VERSION ""

NS_ :

BS_:

BU_: AEB_ECU ABS_ECU ECM EPS_ECU IPC BCM CGW Vector__XXX

/* ─────────────────────────────────────────────────────────────────────
 *  SUV2026 — CAN-HS1 (ADAS Safety Bus) — 500 Kbps
 *  Source: ADAS_HS1_Communication_Matrix_v1.0
 *  Version: 1.0.0
 *  Author: Network Architecture Team
 *  Status: TRAINING REFERENCE
 * ───────────────────────────────────────────────────────────────────── */

/* ─── MESSAGES ─────────────────────────────────────────────────────── */

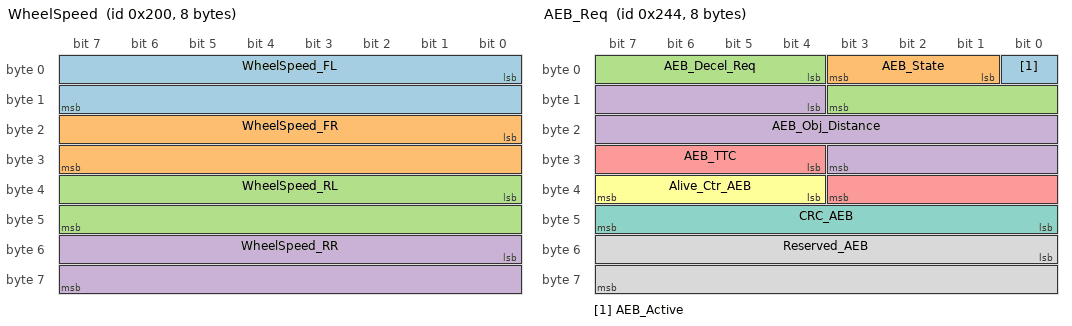
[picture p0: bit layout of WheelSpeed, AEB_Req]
BO_ 512 WheelSpeed: 8 ABS_ECU
 SG_ WheelSpeed_FL : 0|16@1+  (0.01,0) [0|300]    "km/h"  AEB_ECU,ECM,EPS_ECU,CGW
 SG_ WheelSpeed_FR : 16|16@1+ (0.01,0) [0|300]    "km/h"  AEB_ECU,ECM,EPS_ECU,CGW
 SG_ WheelSpeed_RL : 32|16@1+ (0.01,0) [0|300]    "km/h"  AEB_ECU,ECM,CGW
 SG_ WheelSpeed_RR : 48|16@1+ (0.01,0) [0|300]    "km/h"  AEB_ECU,ECM,CGW

BO_ 580 AEB_Req: 8 AEB_ECU
 SG_ AEB_Active        : 0|1@1+   (1,0)     [0|1]       ""       CGW,IPC,ECM,BCM
 SG_ AEB_State         : 1|3@1+   (1,0)     [0|7]       ""       CGW,IPC,ECM,BCM
 SG_ AEB_Decel_Req     : 4|8@1+   (0.1,0)   [0|25.5]   "m/s2"   CGW,IPC,ECM
 SG_ AEB_Obj_Distance  : 12|16@1+ (0.01,0)  [0|655.35] "m"      CGW,IPC
 SG_ AEB_TTC           : 28|8@1+  (0.01,0)  [0|2.55]   "s"      CGW,IPC
 SG_ Alive_Ctr_AEB     : 36|4@1+  (1,0)     [0|14]     ""       CGW,IPC
 SG_ CRC_AEB           : 40|8@1+  (1,0)     [0|255]    ""       CGW,IPC
 SG_ Reserved_AEB      : 48|16@1+ (1,0)     [0|65535]  ""       Vector__XXX

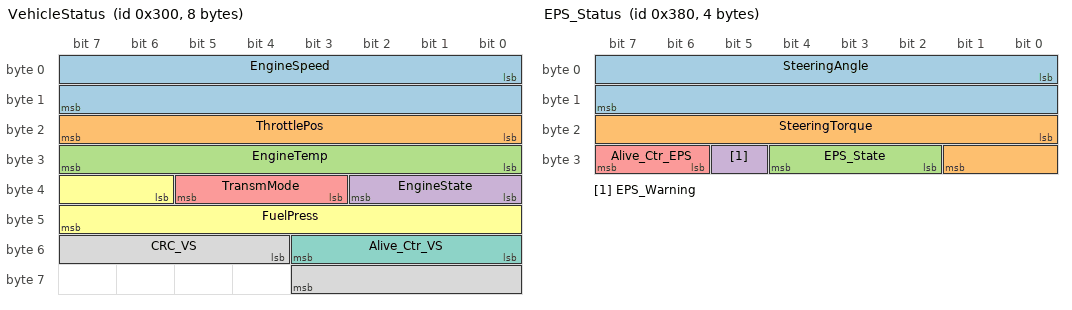
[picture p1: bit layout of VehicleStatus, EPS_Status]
BO_ 768 VehicleStatus: 8 ECM
 SG_ EngineSpeed    : 0|16@1+  (0.25,0)   [0|16383.75] "rpm"   AEB_ECU,IPC,ABS_ECU,CGW
 SG_ ThrottlePos    : 16|8@1+  (0.4,0)    [0|100]      "%"     AEB_ECU,IPC
 SG_ EngineTemp     : 24|8@1+  (0.5,-40)  [-40|87.5]   "degC"  IPC,BCM
 SG_ EngineState    : 32|3@1+  (1,0)      [0|6]        ""      AEB_ECU,IPC,BCM,CGW
 SG_ TransmMode     : 35|3@1+  (1,0)      [0|5]        ""      IPC,BCM
 SG_ FuelPress      : 38|10@1+ (0.1,0)    [0|102.3]    "bar"   IPC
 SG_ Alive_Ctr_VS   : 48|4@1+  (1,0)      [0|14]       ""      AEB_ECU,IPC,CGW
 SG_ CRC_VS         : 52|8@1+  (1,0)      [0|255]      ""      AEB_ECU,IPC,CGW

BO_ 896 EPS_Status: 4 EPS_ECU
 SG_ SteeringAngle  : 0|16@1-  (0.1,0)     [-3276.8|3276.7] "deg"  AEB_ECU,IPC,CGW
 SG_ SteeringTorque : 16|10@1- (0.01,-5.12) [-5.12|5.11]    "Nm"   IPC
 SG_ EPS_State      : 26|3@1+  (1,0)        [0|7]            ""     IPC,CGW,BCM
 SG_ EPS_Warning    : 29|1@1+  (1,0)        [0|1]            ""     IPC,BCM
 SG_ Alive_Ctr_EPS  : 30|2@1+  (1,0)        [0|3]            ""     AEB_ECU

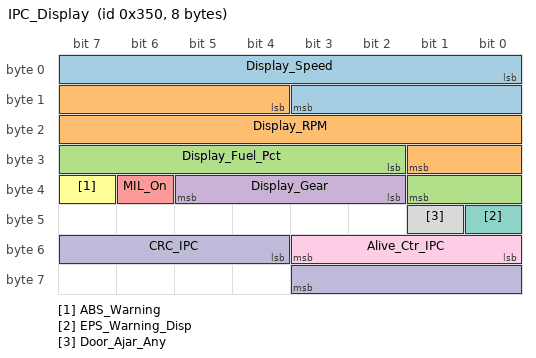
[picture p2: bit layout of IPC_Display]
BO_ 848 IPC_Display: 8 IPC
 SG_ Display_Speed     : 0|12@1+  (0.1,0)  [0|409.5]  "km/h"  CGW
 SG_ Display_RPM       : 12|14@1+ (0.5,0)  [0|8191.5] "rpm"   CGW
 SG_ Display_Fuel_Pct  : 26|8@1+  (0.5,0)  [0|127.5]  "%"     CGW
 SG_ Display_Gear      : 34|4@1+  (1,0)    [0|9]      ""      CGW
 SG_ MIL_On            : 38|1@1+  (1,0)    [0|1]      ""      CGW
 SG_ ABS_Warning       : 39|1@1+  (1,0)    [0|1]      ""      CGW
 SG_ EPS_Warning_Disp  : 40|1@1+  (1,0)    [0|1]      ""      CGW
 SG_ Door_Ajar_Any     : 41|1@1+  (1,0)    [0|1]      ""      CGW
 SG_ Alive_Ctr_IPC     : 48|4@1+  (1,0)    [0|14]     ""      CGW
 SG_ CRC_IPC           : 52|8@1+  (1,0)    [0|255]    ""      CGW

BO_ 1056 BCM_Status: 6 BCM
 SG_ DoorFL_Status  : 0|2@1+  (1,0) [0|3]   ""  CGW,IPC,AEB_ECU
 SG_ DoorFR_Status  : 2|2@1+  (1,0) [0|3]   ""  CGW,IPC
 SG_ DoorRL_Status  : 4|2@1+  (1,0) [0|3]   ""  CGW,IPC
 SG_ DoorRR_Status  : 6|2@1+  (1,0) [0|3]   ""  CGW,IPC
 SG_ Hood_Status    : 8|1@1+  (1,0) [0|1]   ""  CGW,IPC
 SG_ Trunk_Status   : 9|1@1+  (1,0) [0|1]   ""  CGW,IPC
 SG_ IgnitionState  : 10|3@1+ (1,0) [0|4]   ""  CGW,IPC,AEB_ECU
 SG_ HazardActive   : 13|1@1+ (1,0) [0|1]   ""  CGW,IPC
 SG_ LowBeam        : 14|1@1+ (1,0) [0|1]   ""  CGW,IPC
 SG_ HighBeam       : 15|1@1+ (1,0) [0|1]   ""  CGW,IPC
 SG_ WiperState     : 16|3@1+ (1,0) [0|4]   ""  CGW,IPC
 SG_ Alive_Ctr_BCM  : 40|4@1+ (1,0) [0|14]  ""  CGW,IPC
 SG_ CRC_BCM        : 44|8@1+ (1,0) [0|255] ""  CGW,IPC

/* ─── VALUE DEFINITIONS ─────────────────────────────────────────────── */

  0 "OFF"
  1 "STANDBY"
  2 "WARNING"
  3 "ACTIVE"
  4 "FAULT"
  5 "DEGRADED"
  6 "OVERRIDE"
  7 "NOT_AVAILABLE" ;

  0 "OFF"
  1 "CRANKING"
  2 "IDLE"
  3 "RUNNING"
  4 "OVERHEATING"
  5 "SHUTDOWN"
  6 "FAULT" ;

  0 "PARK"
  1 "REVERSE"
  2 "NEUTRAL"
  3 "DRIVE"
  4 "SPORT"
  5 "MANUAL" ;

  0 "INIT"
  1 "ACTIVE"
  2 "DEGRADED"
  3 "FAULT"
  4 "OVERRIDE"
  7 "NOT_AVAILABLE" ;

  0 "PARK"
  1 "REVERSE"
  2 "NEUTRAL"
  3 "DRIVE"
  4 "1st"
  5 "2nd"
  6 "3rd"
  7 "4th"
  8 "5th"
  9 "NOT_AVAILABLE" ;

VAL_ 1056 DoorFL_Status  0 "CLOSED"  1 "OPEN"  2 "AJAR"  3 "NOT_AVAILABLE" ;
VAL_ 1056 DoorFR_Status  0 "CLOSED"  1 "OPEN"  2 "AJAR"  3 "NOT_AVAILABLE" ;
VAL_ 1056 DoorRL_Status  0 "CLOSED"  1 "OPEN"  2 "AJAR"  3 "NOT_AVAILABLE" ;
VAL_ 1056 DoorRR_Status  0 "CLOSED"  1 "OPEN"  2 "AJAR"  3 "NOT_AVAILABLE" ;

  0 "OFF"
  1 "ACC"
  2 "ON"
  3 "START"
  4 "NOT_AVAILABLE" ;

  0 "OFF"
  1 "INTERMITTENT"
  2 "LOW"
  3 "HIGH"
  4 "WASH" ;

/* ─── ATTRIBUTE DEFINITIONS ─────────────────────────────────────────── */

BA_DEF_ BO_  "GenMsgCycleTime"          INT      0 10000;
BA_DEF_ BO_  "GenMsgSendType"           ENUM     "NoMsgSendType","cyclic","event","noMsgSendType";
BA_DEF_ BO_  "GenMsgILSupport"          ENUM     "No","Yes";
BA_DEF_ BO_  "ASIL"                     ENUM     "QM","A","B","C","D";
BA_DEF_ BO_  "FaultReactionTime_ms"     INT      0 1000;
BA_DEF_ BO_  "ApprovalStatus"           ENUM     "DRAFT","IN_REVIEW","APPROVED","RELEASED","OBSOLETE";

BA_DEF_ SG_  "GenSigStartValue"         FLOAT    -1000000 1000000;
BA_DEF_ SG_  "GenSigSendType"           ENUM     "Cyclic","Event","NoSigSendType";
BA_DEF_ SG_  "E2EProfile"               ENUM     "None","P01","P02","P04","P06";

BA_DEF_ BU_  "ILUsed"                   ENUM     "No","Yes";

/* ─── ATTRIBUTE DEFAULTS ─────────────────────────────────────────────── */

BA_DEF_DEF_  "GenMsgCycleTime"          0;
BA_DEF_DEF_  "GenMsgSendType"           "NoMsgSendType";
BA_DEF_DEF_  "GenMsgILSupport"          "No";
BA_DEF_DEF_  "ASIL"                     "QM";
BA_DEF_DEF_  "FaultReactionTime_ms"     0;
BA_DEF_DEF_  "ApprovalStatus"           "DRAFT";
BA_DEF_DEF_  "GenSigStartValue"         0;
BA_DEF_DEF_  "GenSigSendType"           "NoSigSendType";
BA_DEF_DEF_  "E2EProfile"               "None";
BA_DEF_DEF_  "ILUsed"                   "No";

/* ─── MESSAGE ATTRIBUTE VALUES ───────────────────────────────────────── */

BA_ "GenMsgCycleTime"       BO_  512   10;
BA_ "GenMsgCycleTime"       BO_  580   20;
BA_ "GenMsgCycleTime"       BO_  768   10;
BA_ "GenMsgCycleTime"       BO_  896   20;
BA_ "GenMsgCycleTime"       BO_  848   100;
BA_ "GenMsgCycleTime"       BO_  1056  100;

BA_ "GenMsgSendType"        BO_  512   "cyclic";
BA_ "GenMsgSendType"        BO_  580   "cyclic";
BA_ "GenMsgSendType"        BO_  768   "cyclic";
BA_ "GenMsgSendType"        BO_  896   "cyclic";
BA_ "GenMsgSendType"        BO_  848   "cyclic";
BA_ "GenMsgSendType"        BO_  1056  "cyclic";

BA_ "GenMsgILSupport"       BO_  512   "Yes";
BA_ "GenMsgILSupport"       BO_  580   "Yes";
BA_ "GenMsgILSupport"       BO_  768   "Yes";
BA_ "GenMsgILSupport"       BO_  896   "Yes";
BA_ "GenMsgILSupport"       BO_  848   "Yes";
BA_ "GenMsgILSupport"       BO_  1056  "Yes";

BA_ "ASIL"                  BO_  512   "B";
BA_ "ASIL"                  BO_  580   "B";
BA_ "ASIL"                  BO_  768   "A";
BA_ "ASIL"                  BO_  896   "B";

BA_ "FaultReactionTime_ms"  BO_  512   30;
BA_ "FaultReactionTime_ms"  BO_  580   60;
BA_ "FaultReactionTime_ms"  BO_  768   30;
BA_ "FaultReactionTime_ms"  BO_  896   60;

/* ─── SIGNAL INITIAL VALUES ──────────────────────────────────────────── */

BA_ "GenSigStartValue" SG_ 580  AEB_Obj_Distance   65535;
BA_ "GenSigStartValue" SG_ 580  AEB_TTC            255;

BA_ "GenSigStartValue" SG_ 768  EngineTemp         80;

/* ─── E2E PROTECTION ATTRIBUTES ──────────────────────────────────────── */

BA_ "E2EProfile" SG_ 512  WheelSpeed_RR   "P01";
BA_ "E2EProfile" SG_ 580  CRC_AEB         "P01";
BA_ "E2EProfile" SG_ 768  CRC_VS          "P01";
BA_ "E2EProfile" SG_ 896  Alive_Ctr_EPS   "P01";

/* ─── NODE ATTRIBUTES ────────────────────────────────────────────────── */

BA_ "ILUsed" BU_ AEB_ECU "Yes";
BA_ "ILUsed" BU_ ABS_ECU "Yes";
BA_ "ILUsed" BU_ ECM     "Yes";
BA_ "ILUsed" BU_ EPS_ECU "Yes";
BA_ "ILUsed" BU_ IPC     "Yes";
BA_ "ILUsed" BU_ BCM     "Yes";

/* ─── COMMENTS ───────────────────────────────────────────────────────── */

CM_ BU_ AEB_ECU  "Advanced Emergency Braking ECU. Continental Gen4 Radar. ASIL-B.";
CM_ BU_ ABS_ECU  "Anti-lock Braking System ECU. Bosch ESP9.3. Supplies wheel speed.";
CM_ BU_ ECM      "Engine Control Module. Bosch ME17. Supplies powertrain state.";
CM_ BU_ EPS_ECU  "Electric Power Steering ECU. Jtekt. Steering angle source.";
CM_ BU_ IPC      "Instrument Panel Cluster. Marelli. Display commands and warnings.";
CM_ BU_ BCM      "Body Control Module. Continental. Door, light, wiper state.";
CM_ BU_ CGW      "Central Gateway ECU. Routes messages between CAN-HS1 and CAN-HS2.";

CM_ BO_  512   "Wheel speed data. ASIL-B. E2E Profile 01. 10ms cyclic. Source: ABS_ECU.";
CM_ BO_  580   "AEB deceleration request. ASIL-B. E2E Profile 01. 20ms cyclic. Safety-critical.";
CM_ BO_  768   "Engine and transmission status. ASIL-A. E2E Profile 01. 10ms cyclic.";
CM_ BO_  896   "Electric power steering status. ASIL-B. 20ms cyclic. Steering angle source for AEB.";
CM_ BO_  848   "Instrument cluster display commands. QM. 100ms cyclic.";
CM_ BO_  1056  "Body control module status. QM. 100ms cyclic.";

CM_ SG_  512  WheelSpeed_FL      "Front-left wheel speed. 0xFFFF = sensor fault / not available.";
CM_ SG_  512  WheelSpeed_FR      "Front-right wheel speed. 0xFFFF = sensor fault / not available.";
CM_ SG_  512  WheelSpeed_RL      "Rear-left wheel speed. 0xFFFF = not available.";
CM_ SG_  512  WheelSpeed_RR      "Rear-right wheel speed. 0xFFFF = not available.";

CM_ SG_  580  AEB_Active         "1 = AEB actively requesting deceleration. 0 = inactive.";
CM_ SG_  580  AEB_State          "Current AEB system state. See VAL_ for enumeration.";
CM_ SG_  580  AEB_Decel_Req      "Requested deceleration 0–25.5 m/s2. 0xFF = not available.";
CM_ SG_  580  AEB_Obj_Distance   "Distance to nearest obstacle in path (m). 0xFFFF = NA.";
CM_ SG_  580  AEB_TTC            "Time-to-collision (s). 0xFF = no obstacle or not available.";
CM_ SG_  580  Alive_Ctr_AEB      "Alive counter. 0–14 rolling, 15 = signal invalid.";
CM_ SG_  580  CRC_AEB            "E2E CRC checksum. Algorithm: CRC8 SAE-J1850.";
CM_ SG_  580  Reserved_AEB       "Reserved for future use. Always transmit 0x0000.";

CM_ SG_  768  EngineSpeed        "Engine crankshaft speed (rpm). 0xFFFF = not available.";
CM_ SG_  768  ThrottlePos        "Throttle position 0–100% (driver demand).";
CM_ SG_  768  EngineTemp         "Engine coolant temperature. Factor=0.5 Offset=-40. Range -40 to 87.5 degC.";
CM_ SG_  768  EngineState        "Engine operational state. See VAL_ for enumeration.";
CM_ SG_  768  TransmMode         "Transmission selected mode. See VAL_ for enumeration.";
CM_ SG_  768  FuelPress          "Engine fuel rail pressure (bar).";

CM_ SG_  896  SteeringAngle      "Steering wheel angle. Negative=left, Positive=right. Resolution=0.1 deg.";
CM_ SG_  896  SteeringTorque     "Driver steering torque (Nm). Negative=left, Positive=right.";
CM_ SG_  896  EPS_State          "EPS system state. See VAL_ for enumeration.";
CM_ SG_  896  EPS_Warning        "1 = EPS system warning active. Check EPS_State for details.";
CM_ SG_  896  Alive_Ctr_EPS      "2-bit alive counter: 0–3.";

CM_ SG_  848  Display_Speed      "Displayed vehicle speed on cluster (km/h).";
CM_ SG_  848  Display_RPM        "Displayed engine RPM on cluster (rpm).";
CM_ SG_  848  Display_Gear       "Current gear displayed on cluster. See VAL_ for enumeration.";
CM_ SG_  848  MIL_On             "1 = Malfunction Indicator Light (Check Engine) active.";
CM_ SG_  848  ABS_Warning        "1 = ABS warning indicator active.";
CM_ SG_  848  EPS_Warning_Disp   "1 = EPS steering warning indicator active.";
CM_ SG_  848  Door_Ajar_Any      "1 = At least one door is not fully closed.";

CM_ SG_ 1056  DoorFL_Status      "Front-left door status. See VAL_ for CLOSED/OPEN/AJAR/NA.";
CM_ SG_ 1056  DoorFR_Status      "Front-right door status.";
CM_ SG_ 1056  DoorRL_Status      "Rear-left door status.";
CM_ SG_ 1056  DoorRR_Status      "Rear-right door status.";
CM_ SG_ 1056  Hood_Status        "0=closed, 1=open. Used by AEB to inhibit during service.";
CM_ SG_ 1056  IgnitionState      "Current ignition/key state. See VAL_ for enumeration.";
CM_ SG_ 1056  WiperState         "Wiper mode. See VAL_ for OFF/INTERMITTENT/LOW/HIGH/WASH.";
CM_ SG_ 1056  Alive_Ctr_BCM      "Alive counter. 0–14 rolling, 15 = invalid.";
CM_ SG_ 1056  CRC_BCM            "E2E CRC (not used in QM, reserved for future safety upgrade).";
